# km_kpv: IP-XACT component
VLNV tenstorrent.com:ocah:km_kpv:1.0

## Address spaces and blocks
km_kpv_mmap.km_kpv: base 'h0, range 'h1108, width 32

## Registers
Registers are 32-bit, read-write, no defined reset value unless marked. A register's access mark holds for its fields unless they carry their own. Offsets are from the block's base; lines under a group give offsets from that group; [hi:lo] are bit positions; {n}, {i} and the like mark numbered series; 'fields as' and 'values as' point back to an identical list; <NAME> marks a mode.

## km_kpv_mmap.km_kpv — Key entry storage and KM control registers. Access conditioned by lock_write/lock_use.
Base 0x00000000
{0x0+0x40*i} KEY_ENTRY[{i}] (i=0..63) group — One key entry (16 x 32-bit words = 512 bits)
  {0x0+4j} WORD[{j}] (j=0..15) — One 32-bit word of a key entry (512-bit key = 16 words). No reset; powers up random.
    [31:0] data — 32-bit key data word. No reset for security; power-up value undefined. Actual storage is in km_kpv_regfile; CSR field is a protocol placeholder.
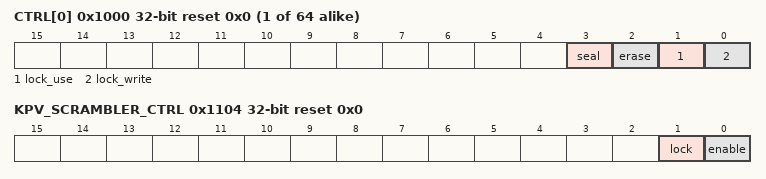
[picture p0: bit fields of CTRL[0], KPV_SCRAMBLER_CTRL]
{0x1000+4i} CTRL[{i}] (i=0..63) access per field reset 0x0 — Per-slot control: lock bits (W1S) and the erase trigger
  [3] seal rw write-1-sets — Seals this key entry until warm reset. Read-any, write-1-only. Setting this bit also sets lock_write in hardware, so a single write seals the slot: its data can be read but not overwritten. Erase remains available, and erasing a sealed slot retires it rather than freeing it (see ERASE), so a sealed slot's material can be destroyed but its slot never reused.
  [2] erase rw write-1-sets — Write-1 to start hardware erase of this slot: an LFSR fills all 16 key words (through the KPV scrambler). Hardware self-clears this bit when the erase completes. Never blocked: neither lock_write, lock_use nor seal prevents an erase. The slot's seal state when the erase completes decides the outcome. Unsealed, the slot CTRL register is cleared and the slot is reusable. Sealed, lock_write stays set and lock_use is set, retiring the slot: its data is destroyed and it can be neither read, rewritten nor reused until warm reset. A seal taken while an erase is already in flight therefore still retires the slot.
  [1] lock_use rw write-1-sets — Prevents KM read of this key entry data until reset. Read-any, write-1-only. Hardware sets this bit when an erase of a sealed slot completes, retiring the slot: its destroyed contents cannot be read back.
  [0] lock_write rw write-1-sets — Prevents KM write to this key entry data until reset; this register stays writable so that a locked slot can still be read-locked and erased. Read-any, write-1-only. Hardware holds this bit set for as long as SEAL is set, so sealing a slot write-locks it without a separate write here.
0x1100 KPV_SCRAMBLER_KEY — 32-bit key for KPV key entry scrambling. No reset; powers up random. Locked when KPV_SCRAMBLER_CTRL.LOCK=1.
  [31:0] key — Scrambler key. No reset for security. HW clears to 0 on wipe via hwclr.
0x1104 KPV_SCRAMBLER_CTRL access per field reset 0x0 — KPV scrambler enable and lock. Reset to 0 on KM reset. LOCK is write-one-only.
  [1] lock rw write-1-sets — Write-one-only. When 1, key and ENABLE cannot be modified until KM reset.
  [0] enable rw — 1 = scramble key entry data on write, descramble on read; 0 = passthrough.

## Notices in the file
SPDX-License-Identifier: Apache-2.0
SPDX-FileCopyrightText: 2026 Tenstorrent USA, Inc.
